# MEC1727N_B0_SZ register map
Vendor: Microchip Technology; Series: MEC172x; File version: 0
CPU: CM4 r1p0, little endian, MPU, FPU, 3 interrupt priority bits, 172 interrupts
Registers are 32-bit, read-write, reset 0x0 unless marked. A register's access mark holds for its fields unless they carry their own. Offsets are from the block's base; [hi:lo] are bit positions; 'fields as' and 'values as' point back to an identical list.

## EC_REG_BANK — This block is designed to be accessed internally by the EC via the register interface.
Base 0x4000FC00
0x00 SRAM_CNFG 8-bit — SRAM Configuration Register
  [1:0] SRAM_SIZE — SRAM Configuration Register: 0: 384KB (352k Code, 32k Data) 1: 320kB (288k Code, 32k Data) 2: 256kB (224k Code, 32k Data) 3: Illegal 256kB (224k Code, 32k Data)
0x04 AHB_ERR_ADDR — AHB Error Address [0:0]
0x14 AHB_ERR_CTRL 8-bit — AHB Error Control [0:0] AHB_ERROR_DISABLE, 0: EC memory exceptions are enabled. 1: EC memory exceptions are disabled.
0x18 INTR_CTRL reset 0x1 — Interrupt Control [0:0] NVIC_EN (NVIC_EN) This bit enables Alternate NVIC IRQ's Vectors. The Alternate NVIC Vectors provides each interrupt event with a dedicated (direct) NVIC vector. 0 = Alternate NVIC vectors disabled, 1= Alternate NVIC vectors enabled
0x1C ETM_CTRL — ETM TRACE Enable [0:0] TRACE_EN (TRACE_EN) This bit enables the ARM TRACE debug port (ETM/ITM). The Trace Debug Interface pins are forced to the TRACE functions. 0 = ARM TRACE port disabled, 1= ARM TRACE port enabled
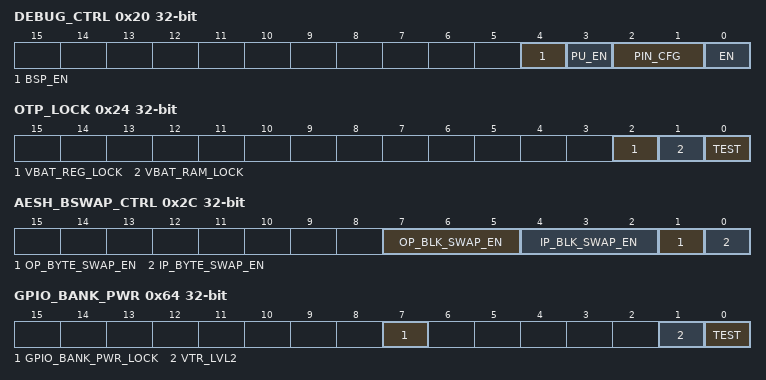
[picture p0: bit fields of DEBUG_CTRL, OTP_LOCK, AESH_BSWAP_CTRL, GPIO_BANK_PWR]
0x20 DEBUG_CTRL — Debug Enable Register
  [4] BSP_EN — This bit sets the boundary scan tap controller accessibility from JTAG port. 1= Boundary scan tap controller accessibile through JTAG Port. 0= Boundary scan tap controller not accessibile through JTAG Port.
  [3] PU_EN — If this bit is set to '1b' internal pull-up resistors are automatically enabled on the appropriate debugging port wires whenever the debug port is enabled (the DEBUG_EN bit in this register is '1b' and the JTAG_RST# pin is high). The setting of DEBUG_PIN_CFG determines which pins have pull-ups enabled when the debug port is enabled.
  [2:1] PIN_CFG — This field determines which pins are affected by the TRST# debug enable pin. 3=Reserved 2=The pins associated with the JTAG TCK and TMS switch to the debug interface when TRST# is de-asserted high. The pins associated with TDI and TDO remain controlled by the associated GPIO. This setting should be used when the ARM Serial Wire Debug (SWD) is required for debugging and the Serial Wire Viewer is not required 1=The pins associated with the JTAG TCK, TMS and TDO switch to the debug interface when TRST# is de-asserted high. The pin associated with TDI remains controlled by the associated GPIO. This setting should be used when the ARM Serial Wire Debug (SWD) and Serial Wire Viewer (SWV) are both required for debugging 0=All four pins associated with JTAG (TCK, TMS, TDI and TDO) switch to the debug interface when TRST# is de-asserted high. This setting should be used when the JTAG TAP controller is required for debugging.
    2=JTAG_TCK_TMS (2=The pins associated with the JTAG TCK and TMS switch to the debug interface when TRST# is de-asserted high. The pins associated with TDI and TDO remain controlled by the associated GPIO. This setting should be used when the ARM Serial Wire Debug (SWD) is required for debugging and the Serial Wire Viewer is not required); 1=JTAG_TCK_TMS_TDO (1=The pins associated with the JTAG TCK, TMS and TDO switch to the debug interface when TRST# is de-asserted high. The pin associated with TDI remains controlled by the associated GPIO. This setting should be used when the ARM Serial Wire Debug (SWD) and Serial Wire Viewer (SWV) are both required for debugging); 0=JTAG_TCK_TMS_TDO_TDI (0=All four pins associated with JTAG (TCK, TMS, TDI and TDO) switch to the debug interface when TRST# is de-asserted high. This setting should be used when the JTAG TAP controller is required for debugging.)
  [0] EN — DEBUG_EN (JTAG_EN) This bit enables the JTAG/SWD debug port. 0= JTAG/SWD port disabled. JTAG/SWD cannot be enabled (i.e., the TRST# pin is ignored and the JTAG signals remain in their non-JTAG state) 1= JTAG/SWD port enabled. A high on TRST# enables JTAG or SWD, as determined by SWD_EN.
0x24 OTP_LOCK — Lock Register
  [2] VBAT_REG_LOCK — VBAT REG LOCK. 0 = Not Locked. 1 = Locked.
  [1] VBAT_RAM_LOCK — VBAT RAM LOCK bit. 0 = Not Locked. 1 = Locked.
  [0] TEST
0x28 WDT_CNT — WDT Event Count [3:0] WDT_COUNT (WDT_COUNT) These EC R/W bits are cleared to 0 on VCC1 POR, but not on a WDT. Note: This field is written by Boot ROM firmware to indicate the number of times a WDT fired before loading a good EC code image.
0x2C AESH_BSWAP_CTRL — AES HASH Byte Swap Control Register.
  [7:5] OP_BLK_SWAP_EN — Used to enable word swap on a DWORD during AHB write from AES / HASH block 0=Disable.
    4=SWAP_128_BYTE_BLOCK (4=Swap 32-bit doublewords in 128-byte blocks); 3=SWAP_64_BYTE_BLOCK (3=Swap doublewords in 64-byte blocks. Useful for SHA-256. Bus references issued in the order 0x3C, 0x38, 0x34, 0x30, 0x2C, 0x28, 0x24, 0x20, 0x1C, 0x18, 0x14, 0x10, 0xC, 0x8, 0x4, 0x0,...); 2=SWAP_16_BYTE_BLOCK (2=Swap doublewords in 16-byte blocks. Useful for AES. Bus references issued in the order 0xC, 0x8, 0x4, 0x0, 0x1C, 0x18,...); 1=SWAP_8_BYTE_BLOCK (1=Swap doublewords in 8-byte blocks. Useful for SHA-512, which works on 64-bit words. Bus references issued in the order 0x4, 0x0, 0xC, 0x8, ...); 0=DIS (0=Disable.)
  [4:2] IP_BLK_SWAP_EN — Used to enable word swap on a DWORD during AHB read from AES / HASH block 0=Disable.
    values as OP_BLK_SWAP_EN
  [1] OP_BYTE_SWAP_EN — Used to enable byte swap on a DWORD during AHB write from AES / HASH block: 1=Enable; 0=Disable.
  [0] IP_BYTE_SWAP_EN — Used to enable byte swap on a DWORD during AHB read from AES / HASH block: 1=Enable; 0=Disable.
0x40 PECI_DIS — PECI Disable
  [0] P_DIS — When this bit is asserted ('1'), it disables the PECI pads to reduce leakage.
0x64 GPIO_BANK_PWR — GPIO Bank Power Register
  [7] GPIO_BANK_PWR_LOCK — GPIO Bank Power Lock. 0: VTR_LEVEL bits[2:0] and GPIO Bank Power Lock bit are R/W 1 = VTR_LEVEL bits[2:0] and GPIO Bank Power Lock bit are Read Only.
  [1] VTR_LVL2 — Voltage value on VTR2. This bit is set by Firmware after a VTR Power On Reset. It must be set by software if the VTR power rail is not active when RESET_SYS is de-asserted. Write access is determined by bit 7. 1=VTR2 is powered by 1.8V 0=VTR2 is powered by 3.3V.
  [0] TEST — This bit must be programmed to 0h for proper operation of the device.
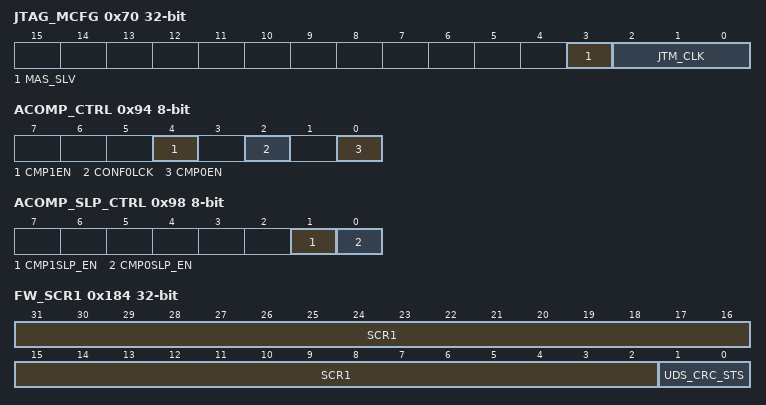
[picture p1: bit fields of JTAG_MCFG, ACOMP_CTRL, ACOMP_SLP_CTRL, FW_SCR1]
0x70 JTAG_MCFG — JTAG Master Configuration Register
  [3] MAS_SLV — This bit controls the direction of the JTAG port. 1=The JTAG Port is configured as a Master 0=The JTAG Port is configures as a Slave.
  [2:0] JTM_CLK — This field determines the JTAG Master clock rate, derived from the 48MHz master clock. 7=375KHz; 6=750KHz; 5=1.5Mhz; 4=3Mhz; 3=6Mhz; 2=12Mhz; 1=24MHz; 0=Reserved.
    7=JTM_CLK_375KHz (7=375KHz); 6=JTM_CLK_750KHz (6=750KHz); 5=JTM_CLK_1MHz (5=1.5Mhz); 4=JTM_CLK_3Mhz (4=3Mhz); 3=JTM_CLK_6Mhz (3=6Mhz); 2=JTM_CLK_12Mhz (2=12Mhz); 1=JTM_CLK_24MHz (1=24MHz)
0x74 JTAG_MSTS ro — JTAG Master Status Register
  [0] JTM_DONE — This bit is set to '1b' when the JTAG Master Command Register is written. It becomes '0b' when shifting has completed. Software can poll this bit to determine when a command has completed and it is therefore safe to remove the data in the JTAG Master TDO Register and load new data into the JTAG Master TMS Register and the JTAG Master TDI Register.
0x78 JTAG_MTDO — JTAG Master TDO Register
  [31:0] JTM_TDO — When the JTAG Master Command Register is written, from 1 to 32 bits are shifted into this register, starting with bit 0, from the JTAG_TDO pin. Shifting is at the rate determined by the JTM_CLK field in the JTAG Master Configuration Register.
0x7C JTAG_MTDI — JTAG Master TDI Register
  [31:0] JTM_TDI — When the JTAG Master Command Register is written, from 1 to 32 bits are shifted out of this register, starting with bit 0, onto the JTAG_TDI pin. Shifting is at the rate determined by the JTM_CLK field in the JTAG Master Configuration Register.
0x80 JTAG_MTMS — JTAG Master TMS Register
  [31:0] JTM_TMS — When the JTAG Master Command Register is written, from 1 to 32 bits are shifted out of this register, starting with bit 0, onto the JTAG_TMS pin. Shifting is at the rate determined by the JTM_CLK field in the JTAG Master Configuration Register.
0x84 JTAG_MCMD — JTAG Master Command Register
  [4:0] JTM_COUNT — If the JTAG Port is configured as a Master, writing this register starts clocking and shifting on the JTAG port. The JTAG Master port will shift JTM_COUNT+1 times, so writing a '0h' will shift 1 bit, and writing '31h' will shift 32 bits. The signal JTAG_CLK will cycle JTM_COUNT+1 times. The contents of the JTAG Master TMS Register and the JTAG Master TDI Register will be shifted out on the falling edge of JTAG_CLK and the.JTAG Master TDO Register will get shifted in on the rising edge of JTAG_CLK. If the JTAG Port is configured as a Slave, writing this register has no effect.
0x90 VW_SRC_CNGF reset 0x7 — Virtual Wire Source Configuration Register
  [2:0] VW_SRC — VWIRE_SOURCE [2], VWIRE_SOURCE [1], VWIRE_SOURCE [0]
0x94 ACOMP_CTRL 8-bit — Comparator Enable
  [4] CMP1EN — Comparator 1 Enable 0: Disable Comparator for operation 1: Enable Comparator operation.
  [2] CONF0LCK — Comparator 0 Configuration Locked 0: Configuration Not Locked. Bits[2,0] are Read-Write 1: Configuration Locked. Bits[2,0] are Read-Only Note: If the CMP_STRAP0 Pin = 1 the Boot ROM writes this bit. Once it is written this bit becomes a read-only bit.
  [0] CMP0EN — Comparator 0 Enable 0: Disable Comparator for operation 1: Enable Comparator operation.
0x98 ACOMP_SLP_CTRL 8-bit — Analog Comparator Sleep Control Register
  [1] CMP1SLP_EN — Comparator 1 Deep Sleep Enable. 0 = Comparator Deep Sleep Disable. 1 = Comparator Deep Sleep Enable.
  [0] CMP0SLP_EN — Comparator 0 Deep Sleep Enable. 0 = Comparator Deep Sleep Disable. 1 = Comparator Deep Sleep Enable. Note: If the CMP_STRAP0 Pin = 1 the Boot ROM writes this bit. Once it is written this bit becomes a read-only bit.
0xB0 EMDRST_EN — Embedded Reset Enable Register
  [0] EN — Embedded Reset Enable Register. 0 = Disable, 1 = Enable.
0xB4 EMDRST_TOUT — Embedded Reset Timeout Register
  [2:0] TOUT — Embedded Reset Timeout Register.
0xB8 EMDRST_STS — Embedded Reset Status Register
  [0] STS — Embedded Reset Status Register.
0xBC EMDRST_CNT — Embedded Reset Count Register
  [18:0] CNT — Embedded Reset CNT Register.
0x180 FW_SCR0 — BOOT ROM Scratch 0 Register
  [31:0] SCR0 — This field has no functionality other than storage. This register is aliased to ESPI Config Scratch Register.
0x184 FW_SCR1 — BOOT ROM Scratch 1 Register
  [31:2] SCR1 — This field has no functionality other than storage. This register is aliased to ESPI Config Scratch Register.
  [1:0] UDS_CRC_STS — UDS CRC status. 0 = UDS CRC checking disabled. Hardware POR state 1 = UDS CRC check passed, 2 = UDS CRC check failed, 3 = invalid. Can only get this result if UDS CRC feature not enabled and bits are set by application code.
0x188 FW_SCR2 — BOOT ROM Scratch 2 Register
  [31:0] SCR2 — This field has no functionality other than storage. This register is aliased to ESPI Config Scratch Register.
0x18C FW_SCR3 — BOOT ROM Scratch 3 Register
  [31:0] SCR3 — This field has no functionality other than storage. This register is aliased to ESPI Config Scratch Register.
